# f28p55x_sys_status_regs register map
Vendor: Texas Instruments
Peripheral module from a debugger description file (folder C2000).
Address unit: 16 bits
Registers are 32-bit, read-write, no defined reset value unless marked. A register's access mark holds for its fields unless they carry their own. Offsets are as the file gives them; lines under a group give offsets from that group; [hi:lo] are bit positions; {n}, {i} and the like mark numbered series; 'fields as' and 'values as' point back to an identical list; <NAME> marks a mode.

## SYS_STATUS_REGS — SYS STATUS Registers
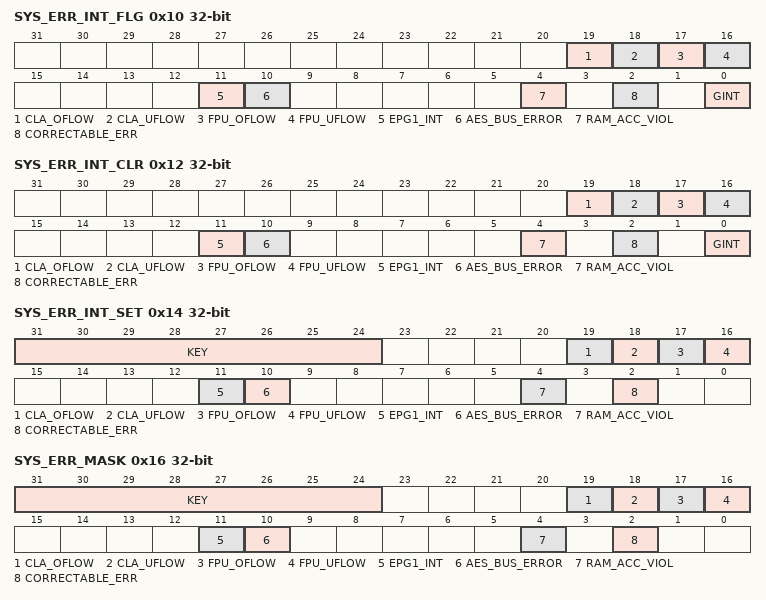
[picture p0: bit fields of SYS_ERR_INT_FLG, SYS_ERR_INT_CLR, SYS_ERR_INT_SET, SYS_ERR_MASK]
0x10 SYS_ERR_INT_FLG ro — Status of interrupts due to multiple different errors in the system.
  [19] CLA_OFLOW — CLA_OFLOW Interrupt flag.
  [18] CLA_UFLOW — CLA_UFLOW Interrupt flag.
  [17] FPU_OFLOW — FPU_OFLOW Interrupt flag.
  [16] FPU_UFLOW — FPU_UFLOW Interrupt flag.
  [11] EPG1_INT — EPG1_INT Interrupt flag.
  [10] AES_BUS_ERROR — AES_BUS_ERROR Interrupt flag.
  [4] RAM_ACC_VIOL — A RAM access vioation flag.
  [2] CORRECTABLE_ERR — RAM/Flash correctable error flag
  [0] GINT — Global Interrupt flag
0x12 SYS_ERR_INT_CLR — SYS_ERR_INT_FLG clear register
  [19] CLA_OFLOW — CLA_OFLOW interrupt flag clear bit
  [18] CLA_UFLOW — CLA_UFLOW interrupt flag clear bit
  [17] FPU_OFLOW — FPU_OFLOW interrupt flag clear bit
  [16] FPU_UFLOW — FPU_UFLOW interrupt flag clear bit
  [11] EPG1_INT — EPG1_INT interrupt flag clear bit
  [10] AES_BUS_ERROR — AES_BUS_ERROR interrupt flag clear bit
  [4] RAM_ACC_VIOL — RAM_ACC_VIOL interrupt flag clear bit
  [2] CORRECTABLE_ERR — CORRECTABLE_ERR interrupt flag clear bit
  [0] GINT — Global Interrupt flag Clear bit
0x14 SYS_ERR_INT_SET — SYS_ERR_INT_FLG set register
  [31:24] KEY
  [19] CLA_OFLOW — CLA_OFLOW interrupt flag set bit
  [18] CLA_UFLOW — CLA_UFLOW interrupt flag set bit
  [17] FPU_OFLOW — FPU_OFLOW interrupt flag set bit
  [16] FPU_UFLOW — FPU_UFLOW interrupt flag set bit
  [11] EPG1_INT — EPG1_INT interrupt flag set bit
  [10] AES_BUS_ERROR — AES_BUS_ERROR interrupt flag set bit
  [4] RAM_ACC_VIOL — RAM_ACC_VIOL interrupt flag set bit
  [2] CORRECTABLE_ERR — CORRECTABLE_ERR interrupt flag set bit
0x16 SYS_ERR_MASK
  [31:24] KEY
  [19] CLA_OFLOW — CLA_OFLOW flag mask bit
  [18] CLA_UFLOW — CLA_UFLOW flag mask bit
  [17] FPU_OFLOW — FPU_OFLOW flag mask bit
  [16] FPU_UFLOW — FPU_UFLOW flag mask bit
  [11] EPG1_INT — EPG1_INT flag mask bit
  [10] AES_BUS_ERROR — AES_BUS_ERROR flag mask bit
  [4] RAM_ACC_VIOL — RAM_ACC_VIOL flag mask bit
  [2] CORRECTABLE_ERR — CORRECTABLE_ERR flag mask bit
